# PCIE1_CORE_VMAP_MMRS register map
Vendor: Texas Instruments
Peripheral module from a debugger description file (folder J721S2).
Registers are 32-bit, read-write, reset 0x0 unless marked. A register's access mark holds for its fields unless they carry their own. Offsets are as the file gives them; lines under a group give offsets from that group; [hi:lo] are bit positions; {n}, {i} and the like mark numbered series; 'fields as' and 'values as' point back to an identical list; <NAME> marks a mode.

## PCIE1_CORE_VMAP_MMRS
0x00 CORE__VMAP__MMRS_ctrl — Control register
  [0] EN — ID enable
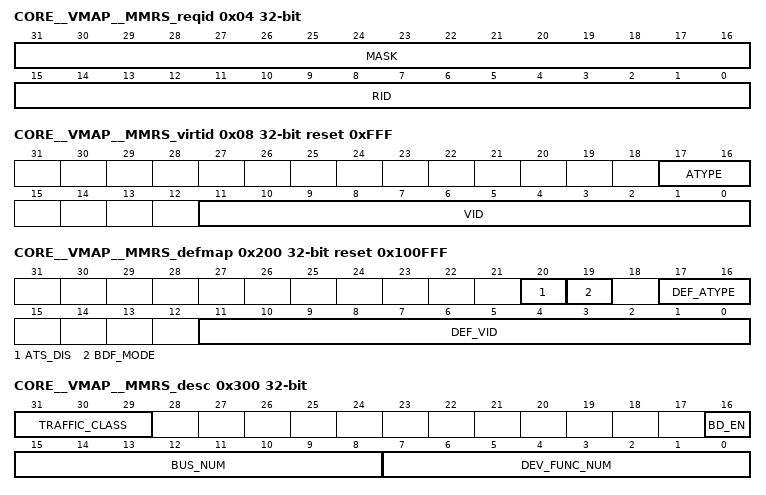
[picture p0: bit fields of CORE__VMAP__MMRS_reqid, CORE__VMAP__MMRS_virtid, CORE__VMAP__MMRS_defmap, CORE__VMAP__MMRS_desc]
0x04 CORE__VMAP__MMRS_reqid — Inbound Requester ID mask and value register
  [31:16] MASK — RequesterID mask
  [15:0] RID — RequesterID
0x08 CORE__VMAP__MMRS_virtid reset 0xFFF — Inbound Virt ID and Atype register
  [17:16] ATYPE — Address type attribute. 0-Physical Address, 1-Intermediate Address, 2-Virtual Address, 3-Translated Address
  [11:0] VID — Match ID
0x200 CORE__VMAP__MMRS_defmap reset 0x100FFF — Inbound virtID default value register
  [20] ATS_DIS — ATS mode. 1-ATS is disabled, 0-ATS is enabled
  [19] BDF_MODE — Bus default mode. 0-Use default bus numbers, 1-Use offset bus numbers
  [17:16] DEF_ATYPE — Default address type attribute. 0-Physical Address, 1-Intermediate Address, 2-Virtual Address, 3-Translated Address
  [11:0] DEF_VID — Default match ID
0x300 CORE__VMAP__MMRS_desc — Outbound ASEL non-zero descriptor register
  [31:29] TRAFFIC_CLASS — PCIe Traffic Class (TC) associated with the non-zero ASEL request.
  [16] BD_EN — External bus and device number enable. This bit enables the client to supply the bus and device numbers to be used in the requester ID. If this bit is 0, the core uses the captured values of the bus and device numbers to form the Requester ID. If this bit is 1, the core uses the bus and device numbers supplied by the client on dev_func_num[7:4] and bus_num[15:8] to form the Requester ID. This bit must always be set while originating requests in the RP mode, and the corresponding Requester ID must be placed on dev_func_num[7:4] and bus_num[15:8].
  [15:8] BUS_NUM — PCI Bus Number associated with the request. When descriptor bit[16] is set, this field must specify the bus number to be used for the Requester ID. Otherwise, this field is ignored by the core.
  [7:0] DEV_FUNC_NUM — PCI Function and Device Number associated with the request. In ARI mode, all 8 bits are used to indicate the requesting function number. In legacy mode, only bits [3:0] are used to specify function number and bits [7:4] are used to specify the device number to be used within the Requester ID, if the descriptor bit[16] is set. If the descriptor bit[16] is not set, then bits[7:4] are ignored.
0x400 CORE__VMAP__MMRS_ob_virtid_match — Outbound virtid match register
  [11:5] VAL — Outbound virtid[11:5] match value. When outbound VBUSM slave interface virtid[11:5] matches the value in this register and the ASEL value is non-zero, the PCIe controller address translation unit (ATU) is bypassed. The PCIe TLP descriptor values are taken from the ext_desc registers.
